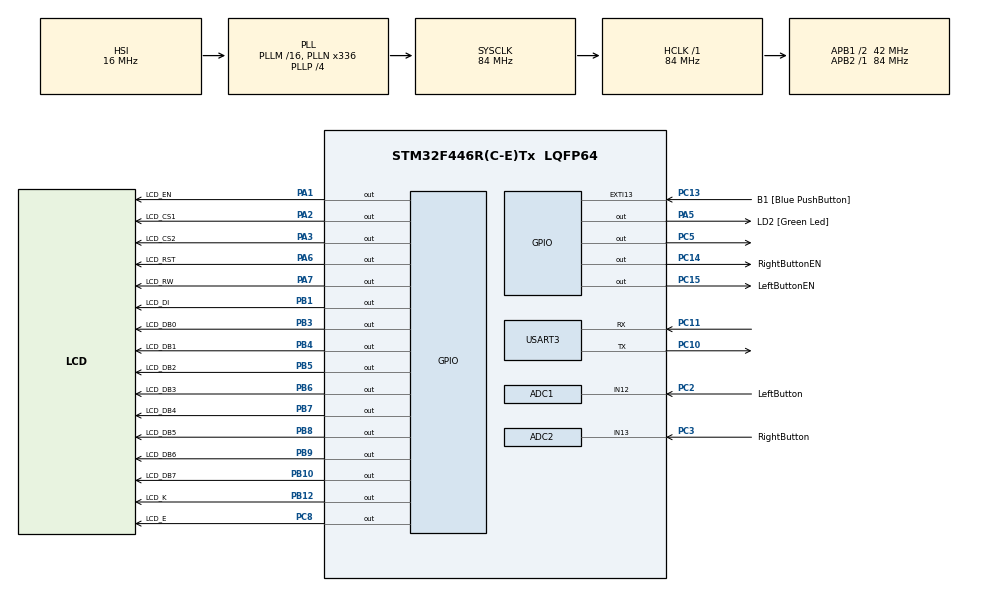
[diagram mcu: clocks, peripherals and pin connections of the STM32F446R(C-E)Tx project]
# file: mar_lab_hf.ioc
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ADC1.Channel-0\#ChannelRegularConversion=ADC_CHANNEL_12
ADC1.ContinuousConvMode=ENABLE
ADC1.DMAContinuousRequests=ENABLE
ADC1.NbrOfConversion=1
ADC1.NbrOfConversionFlag=1
ADC1.Rank-0\#ChannelRegularConversion=1
ADC1.SamplingTime-0\#ChannelRegularConversion=ADC_SAMPLETIME_3CYCLES
ADC1.ScanConvMode=ENABLE
ADC1.master=1
ADC2.Channel-0\#ChannelRegularConversion=ADC_CHANNEL_13
ADC2.ContinuousConvMode=ENABLE
ADC2.DMAContinuousRequests=ENABLE
ADC2.NbrOfConversionFlag=1
ADC2.Rank-0\#ChannelRegularConversion=1
ADC2.SamplingTime-0\#ChannelRegularConversion=ADC_SAMPLETIME_3CYCLES
Dma.ADC1.0.Direction=DMA_PERIPH_TO_MEMORY
Dma.ADC1.0.FIFOMode=DMA_FIFOMODE_DISABLE
Dma.ADC1.0.Instance=DMA2_Stream0
Dma.ADC1.0.MemDataAlignment=DMA_MDATAALIGN_HALFWORD
Dma.ADC1.0.MemInc=DMA_MINC_ENABLE
Dma.ADC1.0.Mode=DMA_CIRCULAR
Dma.ADC1.0.PeriphDataAlignment=DMA_PDATAALIGN_HALFWORD
Dma.ADC1.0.PeriphInc=DMA_PINC_DISABLE
Dma.ADC1.0.Priority=DMA_PRIORITY_HIGH
Dma.ADC2.1.Direction=DMA_PERIPH_TO_MEMORY
Dma.ADC2.1.FIFOMode=DMA_FIFOMODE_DISABLE
Dma.ADC2.1.Instance=DMA2_Stream2
Dma.ADC2.1.MemDataAlignment=DMA_MDATAALIGN_HALFWORD
Dma.ADC2.1.MemInc=DMA_MINC_ENABLE
Dma.ADC2.1.Mode=DMA_CIRCULAR
Dma.ADC2.1.PeriphDataAlignment=DMA_PDATAALIGN_HALFWORD
Dma.ADC2.1.PeriphInc=DMA_PINC_DISABLE
Dma.ADC2.1.Priority=DMA_PRIORITY_HIGH
Dma.Request0=ADC1
Dma.Request1=ADC2
Mcu.Family=STM32F4
Mcu.Name=STM32F446R(C-E)Tx
Mcu.Package=LQFP64
NVIC.DMA2_Stream0_IRQn=true\:0\:0\:false\:false\:true\:false\:true\:true
NVIC.DMA2_Stream2_IRQn=true\:0\:0\:false\:false\:true\:false\:true\:true
NVIC.PriorityGroup=NVIC_PRIORITYGROUP_0
PA1.GPIO_Label=LCD_EN
PA1.Signal=GPIO_Output
PA13.GPIO_Label=TMS
PA13.Mode=Serial_Wire
PA13.Signal=SYS_JTMS-SWDIO
PA14.GPIO_Label=TCK
PA14.Mode=Serial_Wire
PA14.Signal=SYS_JTCK-SWCLK
PA2.GPIO_Label=LCD_CS1
PA2.Signal=GPIO_Output
PA3.GPIO_Label=LCD_CS2
PA3.Signal=GPIO_Output
PA5.GPIO_Label=LD2 [Green Led]
PA5.Signal=GPIO_Output
PA6.GPIO_Label=LCD_RST
PA6.Signal=GPIO_Output
PA7.GPIO_Label=LCD_RW
PA7.Signal=GPIO_Output
PB1.GPIO_Label=LCD_DI
PB1.Signal=GPIO_Output
PB10.GPIO_Label=LCD_DB7
PB10.Signal=GPIO_Output
PB12.GPIO_Label=LCD_K
PB12.Signal=GPIO_Output
PB3.GPIO_Label=LCD_DB0
PB3.Signal=GPIO_Output
PB4.GPIO_Label=LCD_DB1
PB4.Signal=GPIO_Output
PB5.GPIO_Label=LCD_DB2
PB5.Signal=GPIO_Output
PB6.GPIO_Label=LCD_DB3
PB6.Signal=GPIO_Output
PB7.GPIO_Label=LCD_DB4
PB7.Signal=GPIO_Output
PB8.GPIO_Label=LCD_DB5
PB8.Signal=GPIO_Output
PB9.GPIO_Label=LCD_DB6
PB9.Signal=GPIO_Output
PC10.Mode=Asynchronous
PC10.Signal=USART3_TX
PC11.Mode=Asynchronous
PC11.Signal=USART3_RX
PC13.GPIO_Label=B1 [Blue PushButton]
PC13.GPIO_ModeDefaultEXTI=GPIO_MODE_IT_FALLING
PC13.Signal=GPXTI13
PC14-OSC32_IN.GPIO_Label=RightButtonEN
PC14-OSC32_IN.Signal=GPIO_Output
PC15-OSC32_OUT.GPIO_Label=LeftButtonEN
PC15-OSC32_OUT.Signal=GPIO_Output
PC2.GPIO_Label=LeftButton
PC2.Signal=SharedAnalog_PC2
PC3.GPIO_Label=RightButton
PC3.Signal=SharedAnalog_PC3
PC5.Signal=GPIO_Output
PC8.GPIO_Label=LCD_E
PC8.Signal=GPIO_Output
PH0-OSC_IN.Mode=HSE-External-Oscillator
PH0-OSC_IN.Signal=RCC_OSC_IN
PH1-OSC_OUT.Mode=HSE-External-Oscillator
PH1-OSC_OUT.Signal=RCC_OSC_OUT
ProjectManager.HeapSize=0x200
ProjectManager.StackSize=0x400
ProjectManager.TargetToolchain=STM32CubeIDE
RCC.48MHZClocksFreq_Value=84000000
RCC.AHBFreq_Value=84000000
RCC.APB1CLKDivider=RCC_HCLK_DIV2
RCC.APB1Freq_Value=42000000
RCC.APB1TimFreq_Value=84000000
RCC.APB2Freq_Value=84000000
RCC.APB2TimFreq_Value=84000000
RCC.CortexFreq_Value=84000000
RCC.FLatency-AdvancedSettings=FLASH_LATENCY_2
RCC.HCLKFreq_Value=84000000
RCC.HSE_VALUE=8000000
RCC.HSI_VALUE=16000000
RCC.PLLN=336
RCC.PLLP=RCC_PLLP_DIV4
RCC.SYSCLKFreq_VALUE=84000000
RCC.SYSCLKSource=RCC_SYSCLKSOURCE_PLLCLK
RCC.USBFreq_Value=168000000
RCC.VCOOutputFreq_Value=336000000
SH.SharedAnalog_PC2.0=GPIO_Analog
SH.SharedAnalog_PC2.1=ADC1_IN12,IN12
SH.SharedAnalog_PC3.0=GPIO_Analog
SH.SharedAnalog_PC3.1=ADC2_IN13,IN13
USART3.VirtualMode=VM_ASYNC
board=NUCLEO-F446RE

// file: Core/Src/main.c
/* USER CODE BEGIN Header */
/**
  ******************************************************************************
  * @file           : main.c
  * @brief          : Main program body
  ******************************************************************************
  * @attention
  *
  * <h2><center>&copy; Copyright (c) 2021 STMicroelectronics.
  * All rights reserved.</center></h2>
  *
  * This software component is licensed by ST under BSD 3-Clause license,
  * the "License"; You may not use this file except in compliance with the
  * License. You may obtain a copy of the License at:
  *                        opensource.org/licenses/BSD-3-Clause
  *
  ******************************************************************************
  */
/* USER CODE END Header */
#include "main.h"
#include "adc.h"
#include "dma.h"
#include "usart.h"
#include "gpio.h"

void SystemClock_Config(void);

/* USER CODE BEGIN 0 */
#include "Ball.h"
#include "Map.h"
#include "Display.h"
#include "Bat.h"
#include "Brick.h"
#include "bsp_uart.h"
#include "mainloop.h"
/* USER CODE END 0 */

int main(void)
{

  /* MCU Configuration--------------------------------------------------------*/

  /* Reset of all peripherals, Initializes the Flash interface and the Systick. */
  HAL_Init();

  /* Configure the system clock */
  SystemClock_Config();

  /* Initialize all configured peripherals */
  MX_GPIO_Init();
  MX_DMA_Init();
  MX_ADC1_Init();
  MX_ADC2_Init();
  MX_USART3_UART_Init();
  /* USER CODE BEGIN 2 */
  UART_Init();
/*  while(1)
  {

  if(lastReceivedUartCommand=='r')
   {
	  lastReceivedUartCommand=0;

  mainloop_init();*/
  mainloop_init_PCB();
  /* USER CODE END 2 */

  /* Infinite loop */
	  while (1)
	  {

    /* USER CODE BEGIN 3 */
		  //mainloop_go();
		  mainloop_go_PCB();

	  }

  /* USER CODE END 3 */
}

void SystemClock_Config(void)
{
  RCC_OscInitTypeDef RCC_OscInitStruct = {0};
  RCC_ClkInitTypeDef RCC_ClkInitStruct = {0};

  /** Configure the main internal regulator output voltage
  */
  __HAL_RCC_PWR_CLK_ENABLE();
  __HAL_PWR_VOLTAGESCALING_CONFIG(PWR_REGULATOR_VOLTAGE_SCALE3);

  /** Initializes the RCC Oscillators according to the specified parameters
  * in the RCC_OscInitTypeDef structure.
  */
  RCC_OscInitStruct.OscillatorType = RCC_OSCILLATORTYPE_HSI;
  RCC_OscInitStruct.HSIState = RCC_HSI_ON;
  RCC_OscInitStruct.HSICalibrationValue = RCC_HSICALIBRATION_DEFAULT;
  RCC_OscInitStruct.PLL.PLLState = RCC_PLL_ON;
  RCC_OscInitStruct.PLL.PLLSource = RCC_PLLSOURCE_HSI;
  RCC_OscInitStruct.PLL.PLLM = 16;
  RCC_OscInitStruct.PLL.PLLN = 336;
  RCC_OscInitStruct.PLL.PLLP = RCC_PLLP_DIV4;
  RCC_OscInitStruct.PLL.PLLQ = 2;
  RCC_OscInitStruct.PLL.PLLR = 2;
  if (HAL_RCC_OscConfig(&RCC_OscInitStruct) != HAL_OK)
  {
    Error_Handler();
  }

  /** Initializes the CPU, AHB and APB buses clocks
  */
  RCC_ClkInitStruct.ClockType = RCC_CLOCKTYPE_HCLK|RCC_CLOCKTYPE_SYSCLK
                              |RCC_CLOCKTYPE_PCLK1|RCC_CLOCKTYPE_PCLK2;
  RCC_ClkInitStruct.SYSCLKSource = RCC_SYSCLKSOURCE_PLLCLK;
  RCC_ClkInitStruct.AHBCLKDivider = RCC_SYSCLK_DIV1;
  RCC_ClkInitStruct.APB1CLKDivider = RCC_HCLK_DIV2;
  RCC_ClkInitStruct.APB2CLKDivider = RCC_HCLK_DIV1;

  if (HAL_RCC_ClockConfig(&RCC_ClkInitStruct, FLASH_LATENCY_2) != HAL_OK)
  {
    Error_Handler();
  }
}

void Error_Handler(void)
{
  __disable_irq();
  while (1)
  {
  }
}
